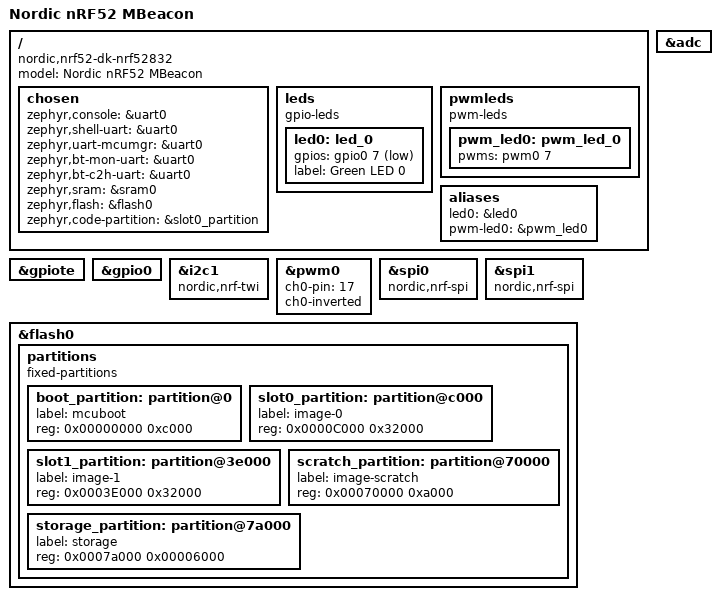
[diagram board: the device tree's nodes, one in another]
/*
 * Copyright (c) 2017 Shawn Nock <shawn@monadnock.ca>
 * Copyright (c) 2017 Linaro Limited
 *
 * SPDX-License-Identifier: Apache-2.0
 */

/dts-v1/;
#include <nordic/nrf52832_qfaa.dtsi>

/ {
	model = "Nordic nRF52 MBeacon";
	compatible = "nordic,nrf52-dk-nrf52832";

	chosen {
		zephyr,console = &uart0;
		zephyr,shell-uart = &uart0;
		zephyr,uart-mcumgr = &uart0;
		zephyr,bt-mon-uart = &uart0;
		zephyr,bt-c2h-uart = &uart0;
		zephyr,sram = &sram0;
		zephyr,flash = &flash0;
		zephyr,code-partition = &slot0_partition;
	};

	leds {
		compatible = "gpio-leds";
		led0: led_0 {
			gpios = <&gpio0 7 GPIO_ACTIVE_LOW>;
			label = "Green LED 0";
		};
	};

	pwmleds {
		compatible = "pwm-leds";
		pwm_led0: pwm_led_0 {
			pwms = <&pwm0 7>;
		};
	};

	/* These aliases are provided for compatibility with samples */
	aliases {
		led0 = &led0;
		pwm-led0 = &pwm_led0;
	};
};

&adc {
	status = "okay";
};

&gpiote {
	status = "okay";
};

&gpio0 {
	status = "okay";
};

&i2c1 {
	compatible = "nordic,nrf-twi";
	/* Cannot be used together with spi1. */
	/* status = "okay"; */
};

&pwm0 {
	status = "okay";
	ch0-pin = <17>;
	ch0-inverted;
};

&spi0 {
	compatible = "nordic,nrf-spi";
	/* Cannot be used together with i2c0. */
	/* status = "disabled"; */
};

&spi1 {
	compatible = "nordic,nrf-spi";
};

&flash0 {

	partitions {
		compatible = "fixed-partitions";
		#address-cells = <1>;
		#size-cells = <1>;

		boot_partition: partition@0 {
			label = "mcuboot";
			reg = <0x00000000 0xc000>;
		};
		slot0_partition: partition@c000 {
			label = "image-0";
			reg = <0x0000C000 0x32000>;
		};
		slot1_partition: partition@3e000 {
			label = "image-1";
			reg = <0x0003E000 0x32000>;
		};
		scratch_partition: partition@70000 {
			label = "image-scratch";
			reg = <0x00070000 0xa000>;
		};
		storage_partition: partition@7a000 {
			label = "storage";
			reg = <0x0007a000 0x00006000>;
		};
	};
};
